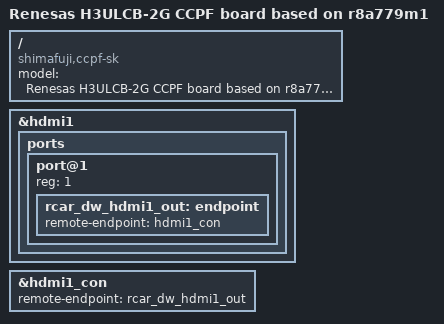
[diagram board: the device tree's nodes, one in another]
// SPDX-License-Identifier: GPL-2.0
/*
 * Device Tree Source for the H3ULCB-2G CCPF SK(ULCB extension) board
 *
 * Copyright (C) 2021 Renesas Electronics Corp.
 */

#include "r8a779m1-ulcb.dts"
#include "ulcb-ccpf-sk.dtsi"

/ {
	model = "Renesas H3ULCB-2G CCPF board based on r8a779m1";
	compatible = "shimafuji,ccpf-sk", "renesas,h3ulcb",
		     "renesas,r8a779m1", "renesas,r8a7795";
};

&hdmi1 {
	status = "okay";

	ports {
		port@1 {
			reg = <1>;
			rcar_dw_hdmi1_out: endpoint {
				remote-endpoint = <&hdmi1_con>;
			};
		};
	};
};

&hdmi1_con {
	remote-endpoint = <&rcar_dw_hdmi1_out>;
};
